VERSION ""

NS_ :

BS_:

BU_: XXX

BO_ 85 CID_WFBMXE: 8 XXX
 SG_ sig_bhxdqy : 40|1@1+ (1,0) [0|1] "" XXX
 SG_ sig_cgbcfk : 56|8@1+ (1,0) [0|255] "" XXX

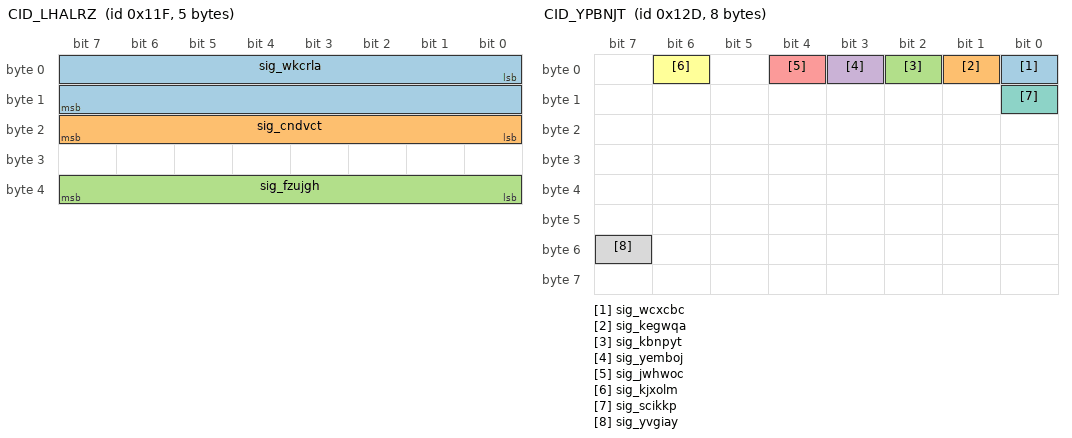
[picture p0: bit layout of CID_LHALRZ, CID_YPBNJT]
BO_ 287 CID_LHALRZ: 5 XXX
 SG_ sig_wkcrla : 0|16@1- (0.1,0) [-450|450] "" XXX
 SG_ sig_cndvct : 16|8@1+ (4,0) [0|1020] "" XXX
 SG_ sig_fzujgh : 32|8@1+ (1,0) [0|255] "" XXX

BO_ 289 CID_TJCRQZ: 8 XXX
 SG_ sig_dpfsnv : 0|12@1+ (1,0) [0|255] "" XXX

BO_ 301 CID_YPBNJT: 8 XXX
 SG_ sig_wcxcbc : 0|1@0+ (1,0) [0|1] "" XXX
 SG_ sig_kegwqa : 1|1@0+ (1,0) [0|1] "" XXX
 SG_ sig_kbnpyt : 2|1@0+ (1,0) [0|1] "" XXX
 SG_ sig_yemboj : 3|1@0+ (1,0) [0|1] "" XXX
 SG_ sig_jwhwoc : 4|1@0+ (1,0) [0|1] "" XXX
 SG_ sig_kjxolm : 6|1@0+ (1,0) [0|1] "" XXX
 SG_ sig_scikkp : 8|1@0+ (1,0) [0|1] "" XXX
 SG_ sig_yvgiay : 55|1@0+ (1,0) [0|1] "" XXX

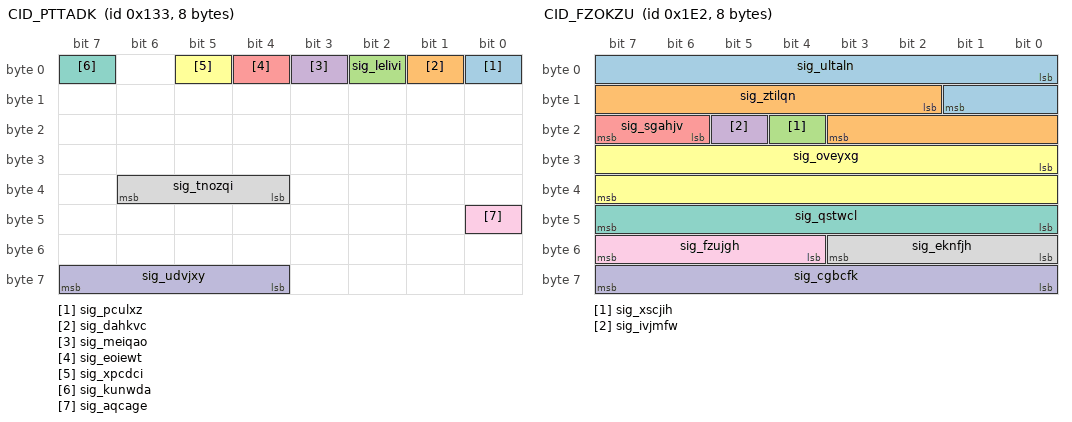
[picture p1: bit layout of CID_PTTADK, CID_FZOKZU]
BO_ 307 CID_PTTADK: 8 XXX
 SG_ sig_pculxz : 0|1@0+ (1,0) [0|1] "" XXX
 SG_ sig_dahkvc : 1|1@1+ (1,0) [0|1] "" XXX
 SG_ sig_lelivi : 2|1@1+ (1,0) [0|1] "" XXX
 SG_ sig_meiqao : 3|1@1+ (1,0) [0|1] "" XXX
 SG_ sig_eoiewt : 4|1@0+ (1,0) [0|1] "" XXX
 SG_ sig_xpcdci : 5|1@0+ (1,0) [0|1] "" XXX
 SG_ sig_kunwda : 7|1@0+ (1,0) [0|1] "" XXX
 SG_ sig_tnozqi : 36|3@1+ (1,0) [0|7] "" XXX
 SG_ sig_aqcage : 40|1@0+ (1,0) [0|1] "" XXX
 SG_ sig_udvjxy : 63|4@0+ (1,0) [0|15] "" XXX

BO_ 482 CID_FZOKZU: 8 XXX
 SG_ sig_ultaln : 0|10@1- (0.01,0) [0|5] "" XXX
 SG_ sig_ztilqn : 10|10@1- (0.01,0) [-5|0] "" XXX
 SG_ sig_xscjih : 20|1@0+ (1,0) [0|1] "" XXX
 SG_ sig_ivjmfw : 21|1@0+ (1,0) [0|1] "" XXX
 SG_ sig_sgahjv : 22|2@1+ (1,0) [0|1] "" XXX
 SG_ sig_oveyxg : 24|16@1- (0.1,0) [-780|779.9] "" XXX
 SG_ sig_qstwcl : 47|8@0+ (1,0) [0|255] "" XXX
 SG_ sig_eknfjh : 48|4@1+ (1,0) [0|15] "" XXX
 SG_ sig_fzujgh : 52|4@1+ (1,0) [0|15] "" XXX
 SG_ sig_cgbcfk : 56|8@1+ (1,0) [0|255] "" XXX

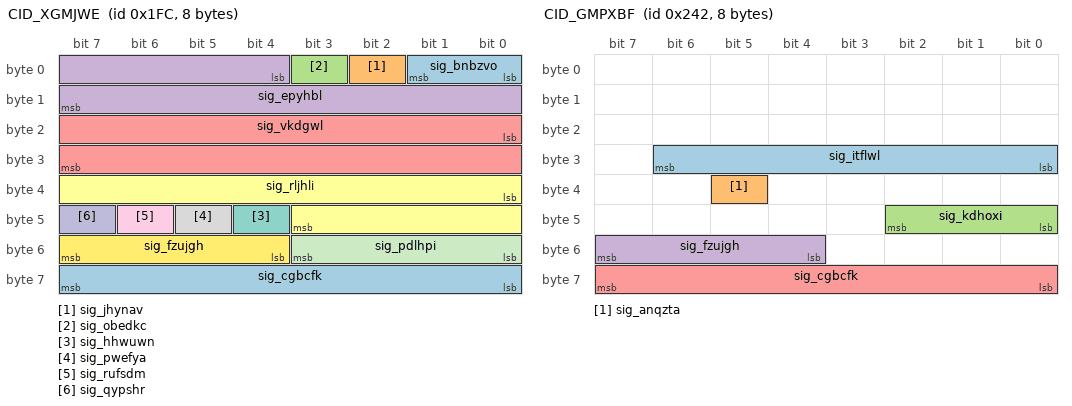
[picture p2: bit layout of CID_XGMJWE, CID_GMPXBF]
BO_ 508 CID_XGMJWE: 8 XXX
 SG_ sig_bnbzvo : 0|2@1+ (1,0) [0|1] "" XXX
 SG_ sig_jhynav : 2|1@1+ (1,0) [0|1] "" XXX
 SG_ sig_obedkc : 3|1@0+ (1,0) [0|1] "" XXX
 SG_ sig_epyhbl : 4|12@1- (1,0) [-2048|2047] "" XXX
 SG_ sig_vkdgwl : 16|16@1- (0.1,0) [-780|779.9] "Deg" XXX
 SG_ sig_rljhli : 32|12@1- (1,0) [0|63] "" XXX
 SG_ sig_hhwuwn : 44|1@0+ (1,0) [0|1] "" XXX
 SG_ sig_pwefya : 45|1@1+ (1,0) [0|255] "" XXX
 SG_ sig_rufsdm : 46|1@1+ (1,0) [0|1] "" XXX
 SG_ sig_qypshr : 47|1@0+ (1,0) [0|3] "" XXX
 SG_ sig_pdlhpi : 48|4@1+ (1,0) [0|15] "" XXX
 SG_ sig_fzujgh : 52|4@1+ (1,0) [0|15] "" XXX
 SG_ sig_cgbcfk : 56|8@1+ (1,0) [0|255] "" XXX

BO_ 578 CID_GMPXBF: 8 XXX
 SG_ sig_itflwl : 30|7@0+ (1,0) [0|127] "" XXX
 SG_ sig_anqzta : 37|1@0+ (1,0) [0|1] "" XXX
 SG_ sig_kdhoxi : 40|3@1+ (1,0) [0|7] "" XXX
 SG_ sig_fzujgh : 55|4@0+ (1,0) [0|15] "" XXX
 SG_ sig_cgbcfk : 56|8@1+ (1,0) [0|255] "" XXX

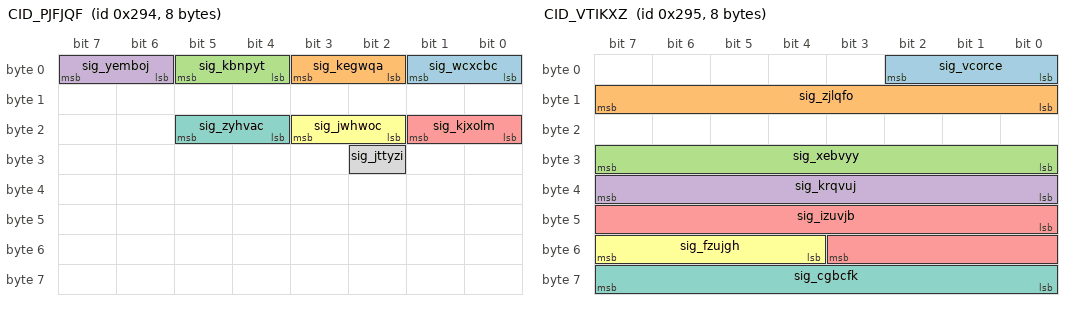
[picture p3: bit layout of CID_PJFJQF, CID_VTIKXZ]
BO_ 660 CID_PJFJQF: 8 XXX
 SG_ sig_wcxcbc : 1|2@0+ (1,0) [0|3] "" XXX
 SG_ sig_kegwqa : 3|2@0+ (1,0) [0|3] "" XXX
 SG_ sig_kbnpyt : 5|2@0+ (1,0) [0|3] "" XXX
 SG_ sig_yemboj : 7|2@0+ (1,0) [0|3] "" XXX
 SG_ sig_kjxolm : 17|2@0+ (1,0) [0|3] "" XXX
 SG_ sig_jwhwoc : 19|2@0+ (1,0) [0|3] "" XXX
 SG_ sig_zyhvac : 21|2@0+ (1,0) [0|3] "" XXX
 SG_ sig_jttyzi : 26|1@0+ (1,0) [0|1] "" XXX

BO_ 661 CID_VTIKXZ: 8 XXX
 SG_ sig_vcorce : 2|3@0+ (1,0) [0|7] "" XXX
 SG_ sig_zjlqfo : 15|8@0+ (1,0) [0|255] "" XXX
 SG_ sig_xebvyy : 31|8@0+ (1,0) [0|255] "" XXX
 SG_ sig_krqvuj : 32|8@1+ (1,0) [0|255] "" XXX
 SG_ sig_izuvjb : 40|12@1+ (1,0) [0|255] "" XXX
 SG_ sig_fzujgh : 52|4@1+ (1,0) [0|15] "" XXX
 SG_ sig_cgbcfk : 63|8@0+ (1,0) [0|255] "" XXX

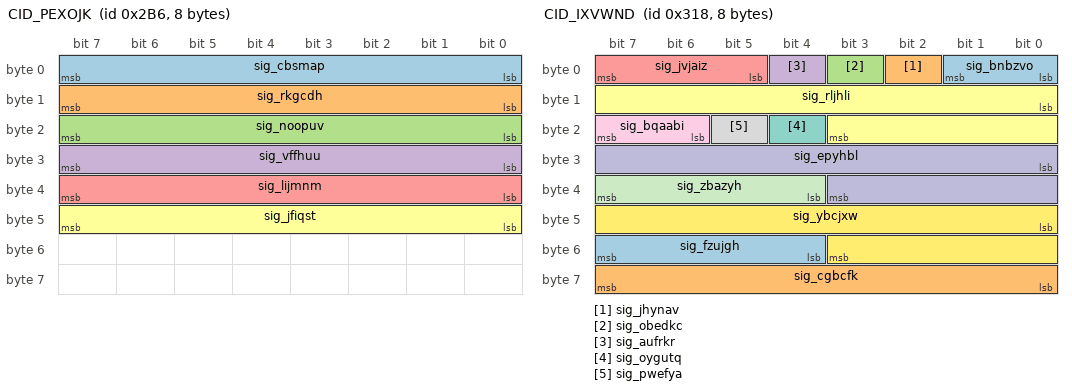
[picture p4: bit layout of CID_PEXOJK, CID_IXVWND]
BO_ 694 CID_PEXOJK: 8 XXX
 SG_ sig_cbsmap : 7|8@0+ (1,0) [0|255] "" XXX
 SG_ sig_rkgcdh : 15|8@0+ (1,0) [0|255] "" XXX
 SG_ sig_noopuv : 23|8@0+ (1,0) [0|255] "" XXX
 SG_ sig_vffhuu : 31|8@0+ (1,0) [0|255] "" XXX
 SG_ sig_lijmnm : 39|8@0+ (1,0) [0|255] "" XXX
 SG_ sig_jfiqst : 47|8@0+ (1,0) [0|255] "" XXX

BO_ 790 CID_DVKRUK: 8 XXX
 SG_ sig_jwxaos : 3|4@0+ (1,0) [0|1] "" XXX
 SG_ sig_uqfqtd : 4|2@1+ (1,0) [0|3] "" XXX
 SG_ sig_vgeyyr : 6|2@1+ (1,0) [0|3] "" XXX
 SG_ sig_vdahwb : 8|2@1+ (1,0) [0|3] "" XXX
 SG_ sig_gqaqhi : 10|1@1+ (1,0) [0|1] "" XXX
 SG_ sig_cszjdd : 11|4@1+ (1,0) [0|1] "" XXX
 SG_ sig_tlwduu : 15|1@0+ (1,0) [0|1] "" XXX
 SG_ sig_oveyxg : 16|11@1- (1,0) [-1024|1023] "" XXX
 SG_ sig_xscjih : 27|1@1+ (1,0) [0|1] "" XXX
 SG_ sig_ivjmfw : 28|1@1+ (1,0) [0|3] "" XXX
 SG_ sig_pmphmy : 29|1@0+ (1,0) [0|1] "" XXX
 SG_ sig_svasrj : 30|1@0+ (1,0) [0|1] "" XXX
 SG_ sig_ugjctt : 31|1@0+ (1,0) [0|1] "" XXX
 SG_ sig_jnwsvr : 32|2@1+ (1,0) [0|3] "" XXX
 SG_ sig_kuzoyu : 34|2@1+ (1,0) [0|3] "" XXX
 SG_ sig_kureph : 36|4@1+ (1,0) [0|3] "" XXX
 SG_ sig_suadop : 40|8@1+ (5,-5) [-5|1270] "" XXX
 SG_ sig_kynmin : 49|2@0+ (1,0) [0|3] "" XXX
 SG_ sig_csjxis : 51|2@0+ (1,0) [0|3] "" XXX
 SG_ sig_fzujgh : 52|4@1+ (1,0) [0|15] "" XXX
 SG_ sig_cgbcfk : 56|8@1+ (1,0) [0|15] "" XXX

BO_ 792 CID_IXVWND: 8 XXX
 SG_ sig_bnbzvo : 0|2@1+ (1,0) [0|1] "" XXX
 SG_ sig_jhynav : 2|1@1+ (1,0) [0|1] "" XXX
 SG_ sig_obedkc : 3|1@1+ (1,0) [0|1] "" XXX
 SG_ sig_aufrkr : 4|1@1+ (1,0) [0|1] "" XXX
 SG_ sig_jvjaiz : 5|3@1+ (1,0) [0|1] "" XXX
 SG_ sig_rljhli : 8|12@1- (1,0) [-2048|2047] "" XXX
 SG_ sig_oygutq : 20|1@1+ (1,0) [0|1] "" XXX
 SG_ sig_pwefya : 21|1@1+ (1,0) [0|1] "" XXX
 SG_ sig_bqaabi : 22|2@1+ (1,0) [0|15] "" XXX
 SG_ sig_epyhbl : 24|12@1- (1,0) [-2048|2047] "" XXX
 SG_ sig_zbazyh : 36|4@1+ (1,0) [0|15] "" XXX
 SG_ sig_ybcjxw : 40|12@1+ (1,0) [0|4095] "" XXX
 SG_ sig_fzujgh : 52|4@1+ (1,0) [0|15] "" XXX
 SG_ sig_cgbcfk : 56|8@1+ (1,0) [0|255] "" XXX

BO_ 813 CID_LTDABG: 8 XXX
 SG_ sig_bajwmq : 0|9@1+ (0.5,0) [0|255.5] "" XXX
 SG_ sig_turexy : 9|1@1+ (1,0) [0|1] "" XXX
 SG_ sig_cbfhjc : 10|3@1+ (1,0) [0|7] "" XXX
 SG_ sig_sruear : 13|3@1+ (1,0) [0|7] "" XXX
 SG_ sig_wbjohw : 16|1@1+ (1,0) [0|1] "" XXX
 SG_ sig_mhcvoc : 17|1@1+ (1,0) [0|1] "" XXX
 SG_ sig_obedkc : 18|1@1+ (1,0) [0|1] "" XXX
 SG_ sig_szjoev : 19|3@1+ (1,0) [0|1] "" XXX
 SG_ sig_mjttal : 22|1@0+ (1,0) [0|1] "" XXX
 SG_ sig_mnhrfd : 23|1@0+ (1,0) [0|1] "" XXX
 SG_ sig_vdahwb : 24|1@1+ (1,0) [0|1] "" XXX
 SG_ sig_ogklnh : 25|7@1+ (1,0) [0|127] "" XXX
 SG_ sig_sprnhx : 32|4@1+ (1,0) [0|15] "" XXX
 SG_ sig_deeflj : 36|12@1+ (1,0) [0|4095] "" XXX
 SG_ sig_fzujgh : 48|4@1+ (1,0) [0|15] "" XXX
 SG_ sig_cekzjr : 55|4@0+ (1,0) [0|15] "" XXX
 SG_ sig_cgbcfk : 56|8@1+ (1,0) [0|255] "" XXX

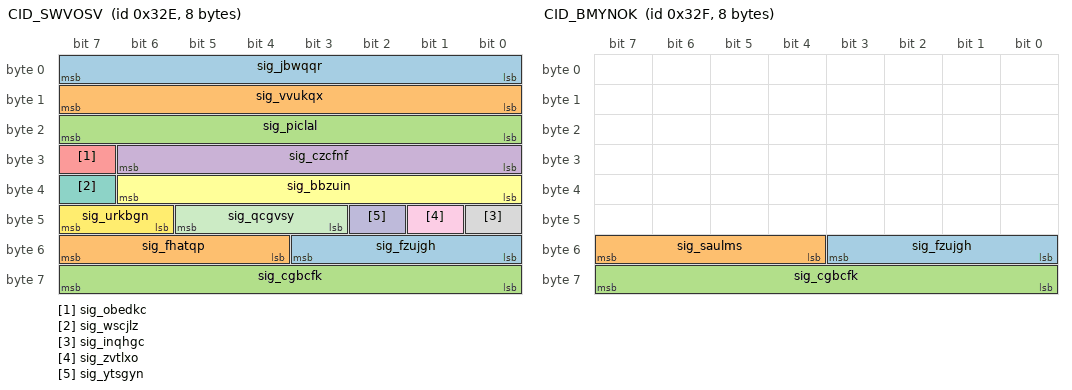
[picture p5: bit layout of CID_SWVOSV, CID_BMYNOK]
BO_ 814 CID_SWVOSV: 8 XXX
 SG_ sig_jbwqqr : 0|8@1+ (0.05,-5) [-100|155] "" XXX
 SG_ sig_vvukqx : 8|8@1+ (0.05,-5) [0|1.26] "" XXX
 SG_ sig_piclal : 16|8@1+ (0.05,-5) [0|1.26] "" XXX
 SG_ sig_czcfnf : 24|7@1+ (0.2,0) [0|12.7] "" XXX
 SG_ sig_obedkc : 31|1@0+ (1,0) [0|1] "" XXX
 SG_ sig_bbzuin : 32|7@1+ (0.2,-16) [0|12.7] "" XXX
 SG_ sig_wscjlz : 39|1@0+ (1,0) [0|1] "" XXX
 SG_ sig_inqhgc : 40|1@0+ (1,0) [0|1] "" XXX
 SG_ sig_zvtlxo : 41|1@0+ (1,0) [0|1] "" XXX
 SG_ sig_ytsgyn : 42|1@1+ (1,0) [0|3] "" XXX
 SG_ sig_qcgvsy : 45|3@0+ (1,0) [0|1] "" XXX
 SG_ sig_urkbgn : 46|2@1+ (1,0) [0|3] "" XXX
 SG_ sig_fzujgh : 48|4@1+ (1,0) [0|15] "" XXX
 SG_ sig_fhatqp : 55|4@0+ (1,0) [0|15] "" XXX
 SG_ sig_cgbcfk : 56|8@1+ (1,0) [0|255] "" XXX

BO_ 815 CID_BMYNOK: 8 XXX
 SG_ sig_fzujgh : 48|4@1+ (1,0) [0|15] "" XXX
 SG_ sig_saulms : 55|4@0+ (1,0) [0|15] "" XXX
 SG_ sig_cgbcfk : 56|8@1+ (1,0) [0|255] "" XXX

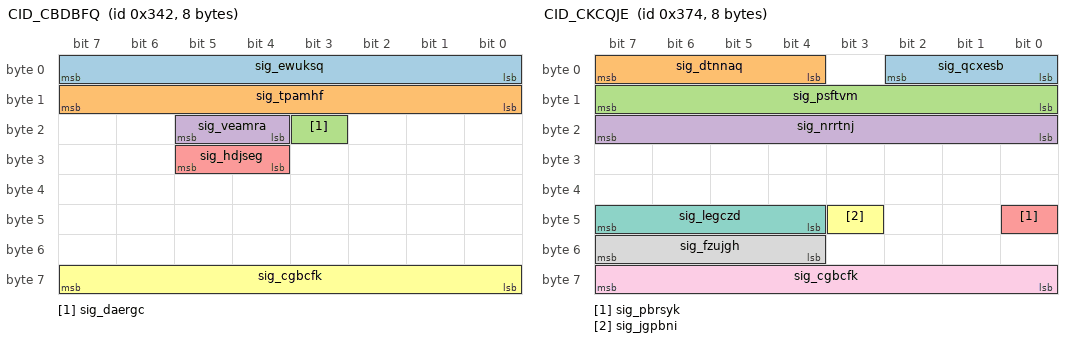
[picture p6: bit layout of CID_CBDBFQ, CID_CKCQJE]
BO_ 834 CID_CBDBFQ: 8 XXX
 SG_ sig_ewuksq : 0|8@1+ (0.01,0) [0|2.55] "" XXX
 SG_ sig_tpamhf : 8|8@1+ (0.01,0) [0|2.55] "" XXX
 SG_ sig_daergc : 19|1@1+ (1,0) [0|1] "" XXX
 SG_ sig_veamra : 20|2@1+ (1,0) [0|255] "" XXX
 SG_ sig_hdjseg : 28|2@1+ (1,0) [0|1] "" XXX
 SG_ sig_cgbcfk : 56|8@1+ (1,0) [0|255] "" XXX

BO_ 884 CID_CKCQJE: 8 MRR
 SG_ sig_qcxesb : 2|3@0+ (1,0) [0|3] "" MRR
 SG_ sig_dtnnaq : 7|4@0+ (1,0) [0|15] "" MRR
 SG_ sig_psftvm : 15|8@0+ (0.1,-12) [0|255] "" MRR
 SG_ sig_nrrtnj : 23|8@0+ (1,-100) [0|255] "" MRR
 SG_ sig_pbrsyk : 40|1@0+ (1,0) [0|3] "" MRR
 SG_ sig_jgpbni : 43|1@0+ (1,0) [0|1] "" XXX
 SG_ sig_legczd : 44|4@1+ (1,0) [0|15] "" XXX
 SG_ sig_fzujgh : 52|4@1+ (1,0) [0|15] "" MRR
 SG_ sig_cgbcfk : 56|8@1+ (1,0) [0|255] "" MRR

BO_ 944 CID_YKFGQN: 8 XXX
 SG_ sig_grnfud : 1|2@0+ (1,0) [0|3] "" XXX
 SG_ sig_reftlq : 2|1@0+ (1,0) [0|1] "" XXX
 SG_ sig_duvpjz : 4|2@0+ (1,0) [0|3] "" XXX
 SG_ sig_gwpysh : 5|1@0+ (1,0) [0|1] "" XXX
 SG_ sig_hztjhf : 6|1@0+ (1,0) [0|1] "" XXX
 SG_ sig_aldprw : 7|1@0+ (1,0) [0|1] "" XXX
 SG_ sig_fdlokf : 8|1@0+ (1,0) [0|1] "" XXX
 SG_ sig_kgieva : 11|3@0+ (1,0) [0|7] "" XXX
 SG_ sig_sopfbr : 12|1@0+ (1,0) [0|1] "" XXX
 SG_ sig_rohpdu : 14|2@0+ (1,0) [0|3] "" XXX
 SG_ sig_lvoypf : 15|1@0+ (1,0) [0|1] "" XXX
 SG_ sig_ibedjy : 16|1@0+ (1,0) [0|1] "" XXX
 SG_ sig_roveyb : 18|2@0+ (1,0) [0|3] "" XXX
 SG_ sig_yyorbq : 19|1@0+ (1,0) [0|1] "" XXX
 SG_ sig_hwluwg : 23|4@0+ (1,0) [0|15] "" XXX
 SG_ sig_eybeyv : 24|28@1+ (1,0) [0|268435455] "" XXX
 SG_ sig_fzujgh : 52|4@1+ (1,0) [0|15] "" XXX
 SG_ sig_cgbcfk : 56|8@1+ (1,0) [0|255] "" XXX

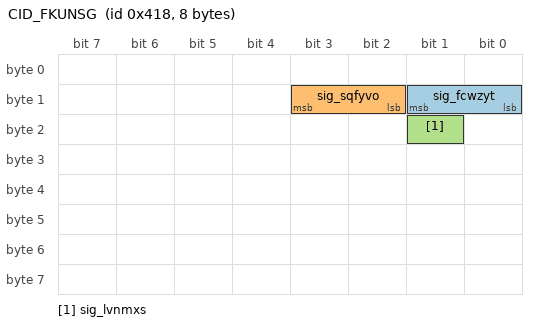
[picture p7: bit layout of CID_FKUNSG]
BO_ 1048 CID_FKUNSG: 8 XXX
 SG_ sig_fcwzyt : 9|2@0+ (1,0) [0|1] "" XXX
 SG_ sig_sqfyvo : 11|2@0+ (1,0) [0|1] "" XXX
 SG_ sig_lvnmxs : 17|1@0+ (1,0) [0|1] "" XXX

VAL_ 578 sig_kdhoxi 4 "D" 2 "R" 3 "N" 1 "P";
VAL_ 790 sig_jwxaos 11 "AutoFullBeamActive" 2 "AutoFullBeamInactive";
VAL_ 790 sig_uqfqtd 0 "GRAY" 1 "GREEN" 2 "YELLOW" 3 "RED";
VAL_ 790 sig_vgeyyr 3 "ALARM_AND_LKA" 2 "LKA" 1 "ALARM" 0 "DISABLE";
VAL_ 790 sig_kuzoyu 0 "GRAY" 1 "GREEN" 2 "YELLOW" 3 "RED";
VAL_ 790 sig_kynmin 0 "VIBRATION" 1 "AUDIO" 2 "AUDIO_AND_VIBRATION";
VAL_ 792 sig_bnbzvo 0 "NotReady" 1 "Ready" 2 "Active" 3 "TemporaryFail";
VAL_ 813 sig_cbfhjc 4 "4BAR" 3 "3BAR" 2 "2BAR" 1 "1BAR";
VAL_ 813 sig_szjoev 0 "OFF" 2 "ACC_ON" 3 "ACC_ACTIVE" 5 "FORCE_ACCEL" 7 "ERROR";
VAL_ 813 sig_ogklnh 36 "ACC_ERROR" 22 "OVERRIDE" 12 "ENGAGE" 8 "DISENGAGE" 20 "ACC_ON" 32 "ACC_OFF" 48 "CHECK_GEAR_D" 16 "FORCE_ACCEL" 0 "NONE";
VAL_ 814 sig_qcgvsy 0 "Off" 1 "Passive" 2 "StandBy" 3 "ActiveControl" 4 "BrakeOnly" 5 "Override" 6 "Standstill" 7 "Failure";
VAL_ 814 sig_urkbgn 0 "Softoff" 1 "Fastoff" 2 "Immediateoff" 3 "Initial";
VAL_ 834 sig_veamra 2 "SPORT" 1 "ECO" 0 "SNOW";
VAL_ 834 sig_hdjseg 3 "HEV" 2 "FORCE_EV" 1 "EV";
VAL_ 944 sig_duvpjz 0 "NOTPRESSED" 1 "DOWN_SETSPEED" 3 "UP_RESETSPEED";
